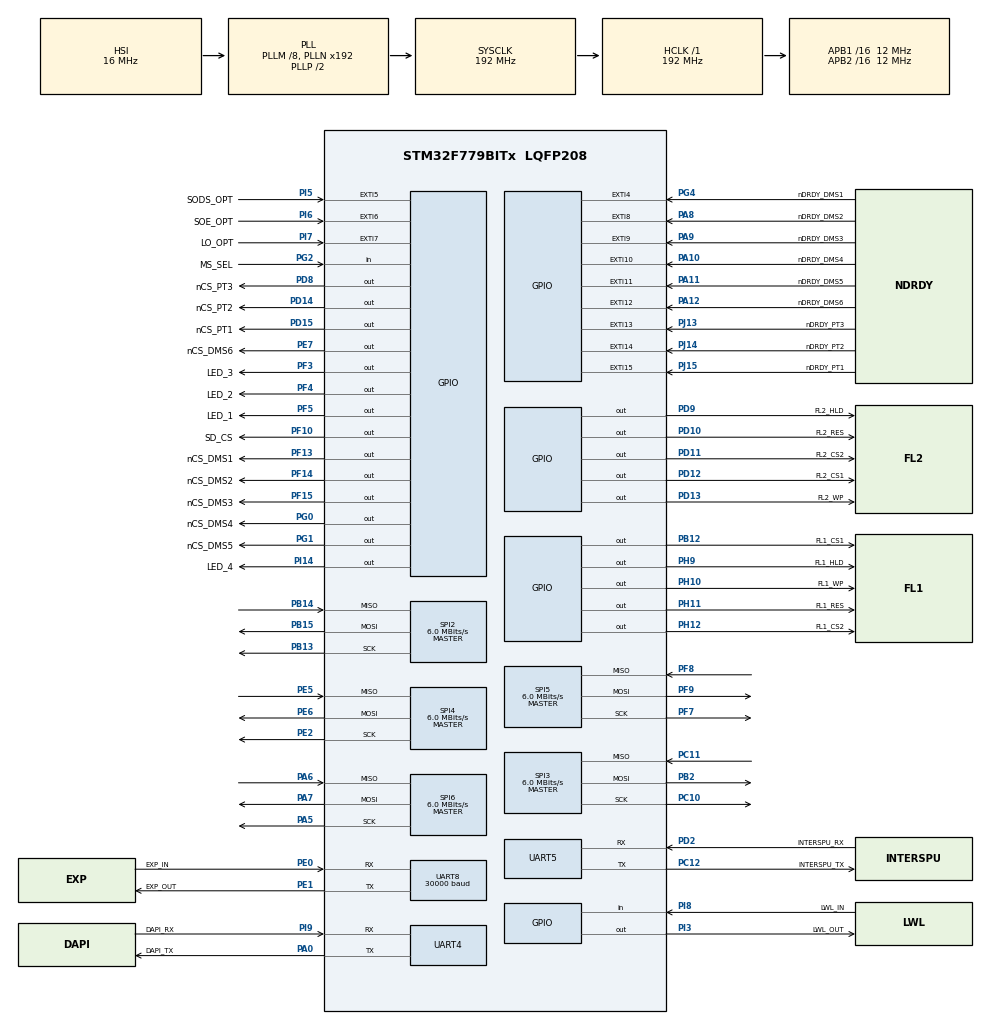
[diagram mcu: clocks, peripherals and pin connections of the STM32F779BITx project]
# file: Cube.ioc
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SPI6.Mode=SPI_MODE_MASTER
PD12.GPIO_Label=FL2_CS1
SPI3.Direction=SPI_DIRECTION_2LINES
SPI4.VirtualType=VM_MASTER
SPI3.VirtualType=VM_MASTER
PH12.Signal=GPIO_Output
SPI2.VirtualType=VM_MASTER
PG4.Signal=GPXTI4
PC12.Signal=UART5_TX
PG0.Signal=GPIO_Output
PI6.GPIO_Label=SOE_OPT
PB13.Signal=SPI2_SCK
RCC.SYSCLKSource=RCC_SYSCLKSOURCE_PLLCLK
NVIC.SPI4_IRQn=true\:6\:0\:true\:false\:true\:true\:true
PJ13.GPIO_Label=nDRDY_PT3
PF7.Signal=SPI5_SCK
PH9.Signal=GPIO_Output
PE2.Mode=Full_Duplex_Master
RCC.APB2TimFreq_Value=24000000
PD8.Signal=GPIO_Output
PE5.Signal=SPI4_MISO
PE1.Signal=UART8_TX
PF10.GPIO_Label=SD_CS
PH10.GPIO_Label=FL1_WP
NVIC.EXTI15_10_IRQn=true\:5\:0\:true\:false\:true\:true\:true
PB2.Signal=SPI3_MOSI
PB3.Mode=JTAG_5_pins
PB12.GPIO_Label=FL1_CS1
PB14.Mode=Full_Duplex_Master
PI6.Signal=GPXTI6
PI3.Signal=GPIO_Output
PG4.GPIO_Label=nDRDY_DMS1
SPI2.CalculateBaudRate=6.0 MBits/s
PE2.Signal=SPI4_SCK
PF8.Mode=Full_Duplex_Master
PA8.Signal=GPXTI8
PF3.Signal=GPIO_Output
PJ14.Signal=GPXTI14
Mcu.Package=LQFP208
SPI2.Mode=SPI_MODE_MASTER
SPI3.Mode=SPI_MODE_MASTER
PD12.Signal=GPIO_Output
PA10.Signal=GPXTI10
PC11.Mode=Full_Duplex_Master
SPI5.CalculateBaudRate=6.0 MBits/s
RCC.APB2CLKDivider=RCC_HCLK_DIV16
PF14.Signal=GPIO_Output
RCC.APB1TimFreq_Value=24000000
PB13.Mode=Full_Duplex_Master
PD15.Signal=GPIO_Output
SPI5.VirtualType=VM_MASTER
NVIC.UART4_IRQn=true\:6\:0\:true\:false\:true\:true\:true
PA5.Mode=Full_Duplex_Master
PD12.PinState=GPIO_PIN_SET
NVIC.EXTI4_IRQn=true\:5\:0\:true\:false\:true\:true\:true
NVIC.UART8_IRQn=true\:6\:0\:true\:false\:true\:true\:true
PD9.GPIO_Label=FL2_HLD
PA9.GPIO_Label=nDRDY_DMS3
PE1.Mode=Asynchronous
PA11.GPIO_Label=nDRDY_DMS5
PF14.GPIO_Label=nCS_DMS2
RCC.APB1CLKDivider=RCC_HCLK_DIV16
PF13.GPIO_Label=nCS_DMS1
PD10.Signal=GPIO_Output
PI8.GPIO_Label=LWL_IN
PA8.GPIO_Label=nDRDY_DMS2
SPI6.CalculateBaudRate=6.0 MBits/s
PH11.GPIO_Label=FL1_RES
PA9.Signal=GPXTI9
PA0/WKUP.Mode=Asynchronous
PB14.Signal=SPI2_MISO
PA5.Signal=SPI6_SCK
PH9.GPIO_Label=FL1_HLD
PJ15.Signal=GPXTI15
PC12.Mode=Asynchronous
PI9.GPIO_Label=DAPI_RX
PE1.GPIO_Label=EXP_OUT
PI7.Signal=GPXTI7
PE6.Mode=Full_Duplex_Master
PF4.GPIO_Label=LED_2
PA0/WKUP.GPIO_Label=DAPI_TX
PF13.Signal=GPIO_Output
PJ15.GPIO_Label=nDRDY_PT1
PA13.Mode=JTAG_5_pins
PD11.Signal=GPIO_Output
PC12.GPIO_Label=INTERSPU_TX
PA11.Signal=GPXTI11
ProjectManager.HeapSize=0x200
PF9.Signal=SPI5_MOSI
SPI6.BaudRatePrescaler=SPI_BAUDRATEPRESCALER_2
NVIC.PriorityGroup=NVIC_PRIORITYGROUP_4
SPI2.DataSize=SPI_DATASIZE_8BIT
PF4.Signal=GPIO_Output
PD2.Signal=UART5_RX
PD2.GPIO_Label=INTERSPU_RX
SPI6.VirtualType=VM_MASTER
Mcu.Family=STM32F7
PA6.Mode=Full_Duplex_Master
NVIC.SPI6_IRQn=true\:6\:0\:true\:false\:true\:true\:true
RCC.CortexFreq_Value=192000000
PH10.Signal=GPIO_Output
PG2.Signal=GPIO_Input
PC10.Signal=SPI3_SCK
SPI4.Direction=SPI_DIRECTION_2LINES
CRC.InputDataFormat=CRC_INPUTDATA_FORMAT_WORDS
PA0/WKUP.Signal=UART4_TX
PI5.GPIO_Label=SODS_OPT
PB15.Signal=SPI2_MOSI
PD11.PinState=GPIO_PIN_SET
PI14.GPIO_Label=LED_4
PJ14.GPIO_Label=nDRDY_PT2
ProjectManager.StackSize=0x400
NVIC.UART5_IRQn=true\:6\:0\:true\:false\:true\:true\:true
PD13.Signal=GPIO_Output
PA12.Signal=GPXTI12
SPI4.Mode=SPI_MODE_MASTER
RCC.HCLKFreq_Value=192000000
PD11.GPIO_Label=FL2_CS2
PI9.Mode=Asynchronous
RCC.AHBFreq_Value=192000000
SPI2.BaudRatePrescaler=SPI_BAUDRATEPRESCALER_2
SPI3.DataSize=SPI_DATASIZE_8BIT
RCC.HSE_VALUE=25000000
PA15.Mode=JTAG_5_pins
PI8.Signal=GPIO_Input
PF9.Mode=Full_Duplex_Master
PB4.Mode=JTAG_5_pins
PA14.Mode=JTAG_5_pins
PI5.Signal=GPXTI5
PA10.GPIO_Label=nDRDY_DMS4
NVIC.SPI2_IRQn=true\:6\:0\:true\:false\:true\:true\:true
SPI4.BaudRatePrescaler=SPI_BAUDRATEPRESCALER_2
PD13.GPIO_Label=FL2_WP
PA6.Signal=SPI6_MISO
UART8.BaudRate=30000
PH12.PinState=GPIO_PIN_SET
PF5.GPIO_Label=LED_1
PA15.Signal=SYS_JTDI
PF8.Signal=SPI5_MISO
PG0.GPIO_Label=nCS_DMS4
PE0.GPIO_Label=EXP_IN
PF5.Signal=GPIO_Output
SPI2.Direction=SPI_DIRECTION_2LINES
PE7.Signal=GPIO_Output
PF3.GPIO_Label=LED_3
PB4.Signal=SYS_JTRST
PG2.GPIO_Label=MS_SEL
PD15.GPIO_Label=nCS_PT1
PA7.Mode=Full_Duplex_Master
PH12.GPIO_Label=FL1_CS2
PH11.Signal=GPIO_Output
SPI4.DataSize=SPI_DATASIZE_16BIT
PG1.Signal=GPIO_Output
PC11.Signal=SPI3_MISO
PI14.Signal=GPIO_Output
PC10.Mode=Full_Duplex_Master
PD9.Signal=GPIO_Output
SPI5.Mode=SPI_MODE_MASTER
PA12.GPIO_Label=nDRDY_DMS6
PD8.GPIO_Label=nCS_PT3
PA13.Signal=SYS_JTMS-SWDIO
PF7.Mode=Full_Duplex_Master
SPI6.DataSize=SPI_DATASIZE_8BIT
ProjectManager.TargetToolchain=STM32CubeIDE
RCC.USBFreq_Value=192000000
PD10.GPIO_Label=FL2_RES
RCC.LSE_VALUE=32768
PD2.Mode=Asynchronous
board=custom
RCC.VCOOutputFreq_Value=384000000
PG1.GPIO_Label=nCS_DMS5
PI9.Signal=UART4_RX
PB15.Mode=Full_Duplex_Master
RCC.APB2Freq_Value=12000000
SPI3.CalculateBaudRate=6.0 MBits/s
PF10.Signal=GPIO_Output
PE5.Mode=Full_Duplex_Master
PF15.GPIO_Label=nCS_DMS3
PI7.GPIO_Label=LO_OPT
SPI6.Direction=SPI_DIRECTION_2LINES
PF15.Signal=GPIO_Output
SPI4.CalculateBaudRate=6.0 MBits/s
PD14.GPIO_Label=nCS_PT2
PE6.Signal=SPI4_MOSI
Mcu.Name=STM32F779BITx
PE0.Signal=UART8_RX
PE7.GPIO_Label=nCS_DMS6
PD14.Signal=GPIO_Output
PB3.Signal=SYS_JTDO-SWO
RCC.SYSCLKFreq_VALUE=192000000
PB2.Mode=Full_Duplex_Master
NVIC.EXTI9_5_IRQn=true\:5\:0\:true\:false\:true\:true\:true
PA14.Signal=SYS_JTCK-SWCLK
RCC.HSI_VALUE=16000000
PI3.GPIO_Label=LWL_OUT
RCC.PLLM=8
RCC.APB1Freq_Value=12000000
VP_CRC_VS_CRC.Mode=CRC_Activate
PB12.Signal=GPIO_Output
PE0.Mode=Asynchronous
PJ13.Signal=GPXTI13
SPI5.Direction=SPI_DIRECTION_2LINES
PA7.Signal=SPI6_MOSI

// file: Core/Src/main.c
/* USER CODE BEGIN Header */
/**
 ******************************************************************************
 * @file           : main.c
 * @brief          : Main program body
 ******************************************************************************
 * @attention
 *
 * <h2><center>&copy; Copyright (c) 2020 STMicroelectronics.
 * All rights reserved.</center></h2>
 *
 * This software component is licensed by ST under Ultimate Liberty license
 * SLA0044, the "License"; You may not use this file except in compliance with
 * the License. You may obtain a copy of the License at:
 *                             www.st.com/SLA0044
 *
 ******************************************************************************
 */
/* USER CODE END Header */
#include "main.h"
#include "crc.h"
#include "spi.h"
#include "usart.h"
#include "gpio.h"

/* USER CODE BEGIN Includes */
#include "Telemetry.h"
#include "test.h"

/* USER CODE END Includes */

void SystemClock_Config(void);

int main(void)
{

  /* MCU Configuration--------------------------------------------------------*/

  /* Reset of all peripherals, Initializes the Flash interface and the Systick. */
  HAL_Init();

  /* Configure the system clock */
  SystemClock_Config();

  /* Initialize all configured peripherals */
  MX_GPIO_Init();
  MX_SPI2_Init();
  MX_SPI3_Init();
  MX_SPI6_Init();
  MX_UART4_Init();
  MX_UART8_Init();
  MX_UART5_Init();
  MX_CRC_Init();
  MX_SPI4_Init();
  MX_SPI5_Init();
  /* USER CODE BEGIN 2 */

  uint32_t ret = Test();
  /* USER CODE END 2 */

  /* Infinite loop */
	while (1) {

	}
}

void SystemClock_Config(void)
{
  RCC_OscInitTypeDef RCC_OscInitStruct = {0};
  RCC_ClkInitTypeDef RCC_ClkInitStruct = {0};
  RCC_PeriphCLKInitTypeDef PeriphClkInitStruct = {0};

  /** Configure the main internal regulator output voltage
  */
  __HAL_RCC_PWR_CLK_ENABLE();
  __HAL_PWR_VOLTAGESCALING_CONFIG(PWR_REGULATOR_VOLTAGE_SCALE1);
  /** Initializes the RCC Oscillators according to the specified parameters
  * in the RCC_OscInitTypeDef structure.
  */
  RCC_OscInitStruct.OscillatorType = RCC_OSCILLATORTYPE_HSI;
  RCC_OscInitStruct.HSIState = RCC_HSI_ON;
  RCC_OscInitStruct.HSICalibrationValue = RCC_HSICALIBRATION_DEFAULT;
  RCC_OscInitStruct.PLL.PLLState = RCC_PLL_ON;
  RCC_OscInitStruct.PLL.PLLSource = RCC_PLLSOURCE_HSI;
  RCC_OscInitStruct.PLL.PLLM = 8;
  RCC_OscInitStruct.PLL.PLLN = 192;
  RCC_OscInitStruct.PLL.PLLP = RCC_PLLP_DIV2;
  RCC_OscInitStruct.PLL.PLLQ = 2;
  if (HAL_RCC_OscConfig(&RCC_OscInitStruct) != HAL_OK)
  {
    Error_Handler();
  }
  /** Activate the Over-Drive mode
  */
  if (HAL_PWREx_EnableOverDrive() != HAL_OK)
  {
    Error_Handler();
  }
  /** Initializes the CPU, AHB and APB buses clocks
  */
  RCC_ClkInitStruct.ClockType = RCC_CLOCKTYPE_HCLK|RCC_CLOCKTYPE_SYSCLK
                              |RCC_CLOCKTYPE_PCLK1|RCC_CLOCKTYPE_PCLK2;
  RCC_ClkInitStruct.SYSCLKSource = RCC_SYSCLKSOURCE_PLLCLK;
  RCC_ClkInitStruct.AHBCLKDivider = RCC_SYSCLK_DIV1;
  RCC_ClkInitStruct.APB1CLKDivider = RCC_HCLK_DIV16;
  RCC_ClkInitStruct.APB2CLKDivider = RCC_HCLK_DIV16;

  if (HAL_RCC_ClockConfig(&RCC_ClkInitStruct, FLASH_LATENCY_6) != HAL_OK)
  {
    Error_Handler();
  }
  PeriphClkInitStruct.PeriphClockSelection = RCC_PERIPHCLK_UART4|RCC_PERIPHCLK_UART5
                              |RCC_PERIPHCLK_UART8;
  PeriphClkInitStruct.Uart4ClockSelection = RCC_UART4CLKSOURCE_PCLK1;
  PeriphClkInitStruct.Uart5ClockSelection = RCC_UART5CLKSOURCE_PCLK1;
  PeriphClkInitStruct.Uart8ClockSelection = RCC_UART8CLKSOURCE_PCLK1;
  if (HAL_RCCEx_PeriphCLKConfig(&PeriphClkInitStruct) != HAL_OK)
  {
    Error_Handler();
  }
}

void Error_Handler(void)
{
}

/************************ (C) COPYRIGHT STMicroelectronics *****END OF FILE****/
